AUTOSAR XML (schema 314)
package /ComponentType
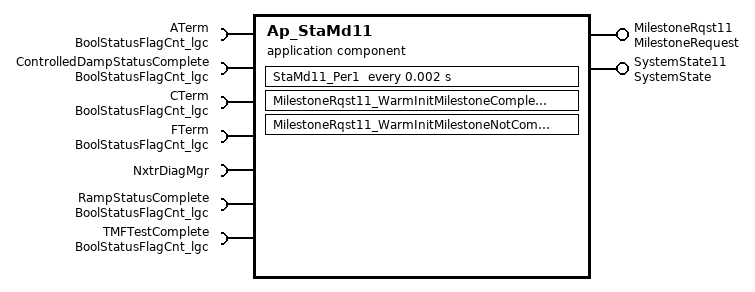
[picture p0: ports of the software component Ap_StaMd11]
  application software component type Ap_StaMd11
    provide port MilestoneRqst11: provided-interface=MilestoneRequest
      provided-com-specs:
        operation=WarmInitMilestoneComplete, queue-length=1
        operation=WarmInitMilestoneNotComplete, queue-length=1
    provide port SystemState11: mode-switch-com-spec{mode-group=Mode, queue-length=1}, provided-interface=SystemState
    7 x require port:
      ATerm: unqueued-receiver-com-spec{data-element=Cnt_lgc, init-value=D_TRUE_CNT_LGC}, required-interface=BoolStatusFlagCnt_lgc
      ControlledDampStatusComplete: unqueued-receiver-com-spec{data-element=Cnt_lgc, init-value=D_FALSE_CNT_LGC}, required-interface=BoolStatusFlagCnt_lgc
      CTerm: unqueued-receiver-com-spec{data-element=Cnt_lgc, init-value=D_FALSE_CNT_LGC}, required-interface=BoolStatusFlagCnt_lgc
      FTerm: unqueued-receiver-com-spec{data-element=Cnt_lgc, init-value=D_FALSE_CNT_LGC}, required-interface=BoolStatusFlagCnt_lgc
      NxtrDiagMgr: required-com-specs=[GetNTCActive, GetNTCFailed, GetNTCStatus, SetNTCStatus], required-interface=NxtrDiagMgr
      RampStatusComplete: unqueued-receiver-com-spec{data-element=Cnt_lgc, init-value=D_FALSE_CNT_LGC}, required-interface=BoolStatusFlagCnt_lgc
      TMFTestComplete: unqueued-receiver-com-spec{data-element=Cnt_lgc, init-value=D_FALSE_CNT_LGC}, required-interface=BoolStatusFlagCnt_lgc
  internal behavior Ap_StaMd11_InternalBehavior: component=Ap_StaMd11
    operation invoked event OIT_MilestoneRqst11_WarmInitMilestoneComplete_MilestoneRqst11_WarmInitMilestoneComplete: start-on-event=MilestoneRqst11_WarmInitMilestoneComplete, operation=MilestoneRqst11.WarmInitMilestoneComplete
    operation invoked event OIT_MilestoneRqst11_WarmInitMilestoneNotComplete_MilestoneRqst11_WarmInitMilestoneNotComplete: start-on-event=MilestoneRqst11_WarmInitMilestoneNotComplete, operation=MilestoneRqst11.WarmInitMilestoneNotComplete
    timing event TMT_StaMd11_Per1: start-on-event=StaMd11_Per1, period=0.002
    exclusive area StaMds11_MilestoneRqst_WARMINIT_ExclArea
    port-api-options:
      enable-take-address=false, indirect-api=false, port=ATerm
      enable-take-address=false, indirect-api=false, port=ControlledDampStatusComplete
      enable-take-address=false, indirect-api=false, port=CTerm
      enable-take-address=false, indirect-api=false, port=FTerm
      enable-take-address=false, indirect-api=false, port=MilestoneRqst11
      enable-take-address=false, indirect-api=false, port=NxtrDiagMgr
      enable-take-address=false, indirect-api=false, port=RampStatusComplete
      enable-take-address=false, indirect-api=false, port=SystemState11
      enable-take-address=false, indirect-api=false, port=TMFTestComplete
    runnable MilestoneRqst11_WarmInitMilestoneComplete: can-be-invoked-concurrently=true, can-enter-exclusive-area=StaMds11_MilestoneRqst_WARMINIT_ExclArea
    runnable MilestoneRqst11_WarmInitMilestoneNotComplete: can-be-invoked-concurrently=true, can-enter-exclusive-area=StaMds11_MilestoneRqst_WARMINIT_ExclArea
    runnable StaMd11_Per1
      6 x data read access:
        READ_ATerm_Cnt_lgc: data-element=ATerm.Cnt_lgc
        READ_ControlledDampStatusComplete_Cnt_lgc: data-element=ControlledDampStatusComplete.Cnt_lgc
        READ_CTerm_Cnt_lgc: data-element=CTerm.Cnt_lgc
        READ_FTerm_Cnt_lgc: data-element=FTerm.Cnt_lgc
        READ_RampStatusComplete_Cnt_lgc: data-element=RampStatusComplete.Cnt_lgc
        READ_TMFTestComplete_Cnt_lgc: data-element=TMFTestComplete.Cnt_lgc
      mode switch point SWITCH_SystemState11_Mode: mode-group=SystemState11.Mode
      sync call SC_NxtrDiagMgr_SetNTCStatus: operation=NxtrDiagMgr.SetNTCStatus, timeout=0
  swc implementation Ap_StaMd11_Implementation: behavior=Ap_StaMd11_InternalBehavior
    code-descriptors:
      code Code: type=SRC
